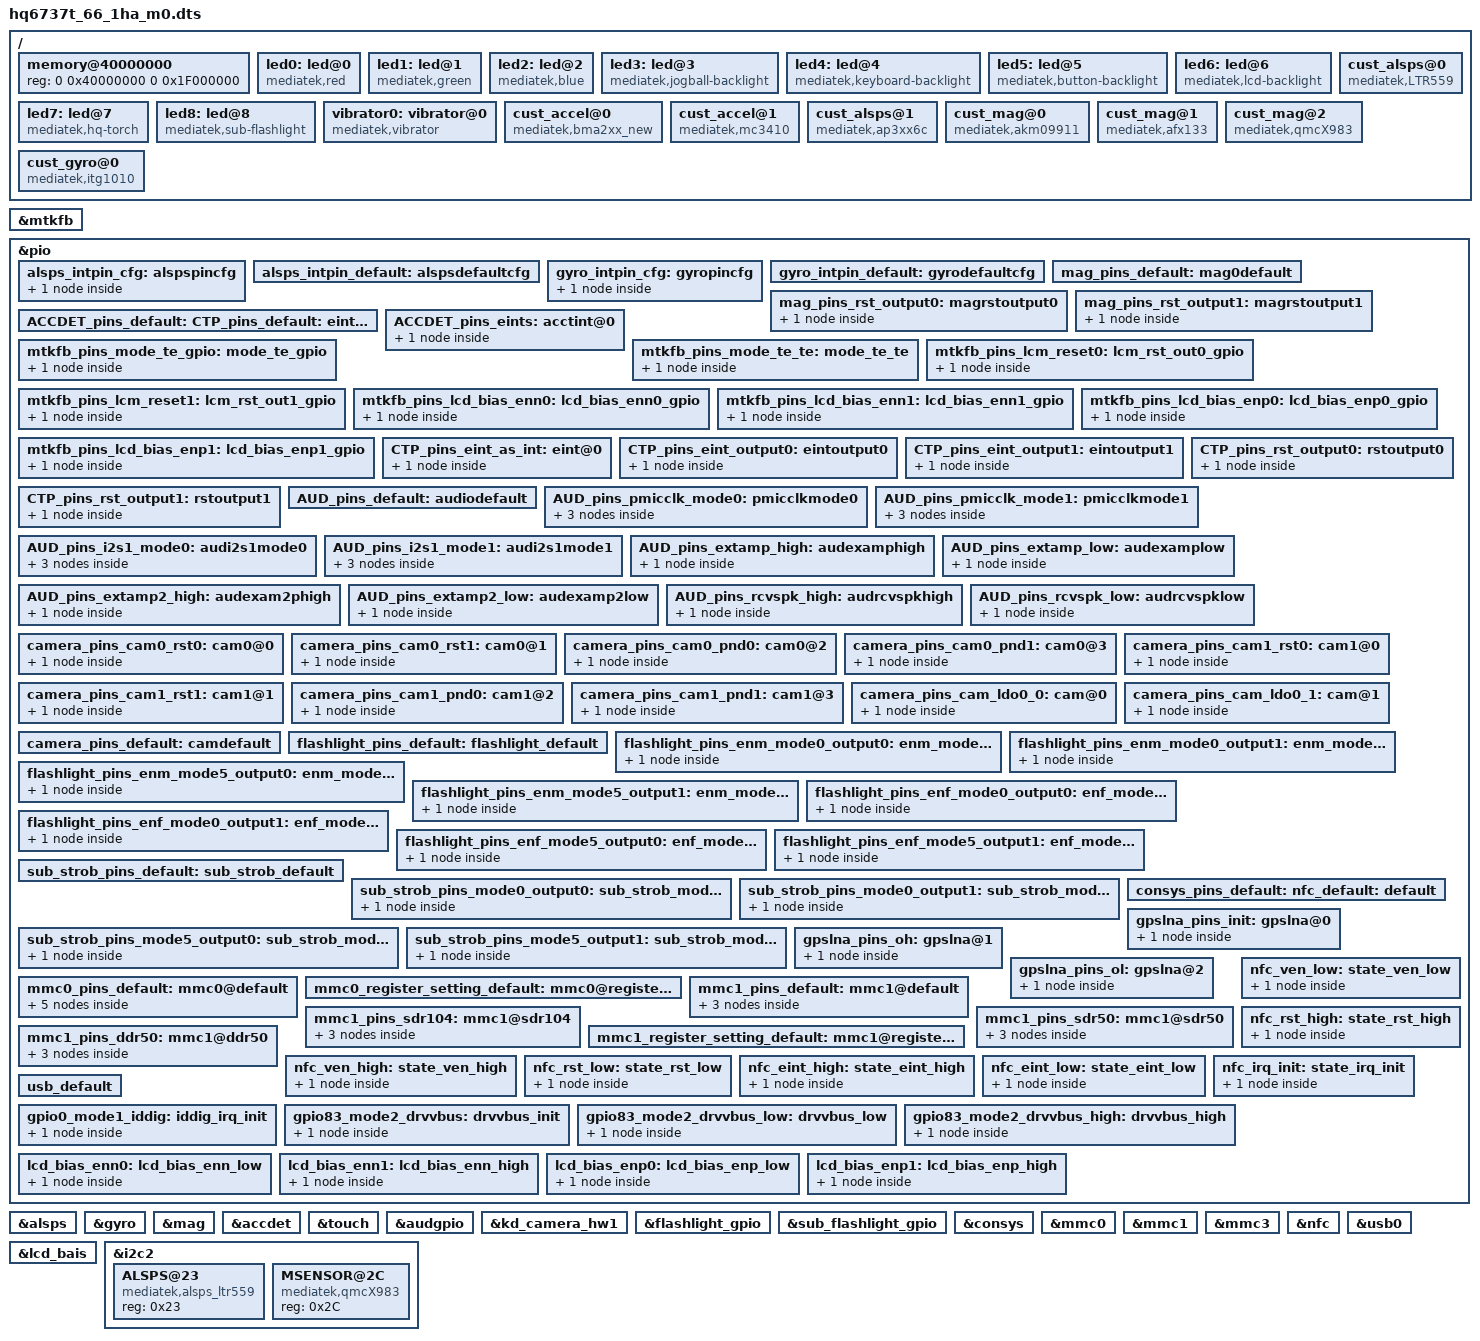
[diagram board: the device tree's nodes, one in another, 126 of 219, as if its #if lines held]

/dts-v1/;

#include "mt6735.dtsi"
#include "cust.dtsi"
#include <dt-bindings/lcm/r63417_fhd_dsi_cmd_truly_nt50358.dtsi>
#include <generated/autoconf.h>
#ifdef CONFIG_MTK_HAFG_20
#include "hq6737t_66_1ha_m0_fg20_bat_setting.dtsi"
#else
#include "hq6737t_66_1ha_m0_fg_oldgauge_bat_setting.dtsi"
#endif

/ {
	memory@40000000 {
		device_type = "memory";
		reg = <0 0x40000000 0 0x1F000000>;
	};

	led0:led@0 {
		compatible = "mediatek,red";
		led_mode = <3>;
		data = <2>;
		pwm_config = <0 0 0 0 0>;
	};
	led1:led@1 {
		compatible = "mediatek,green";
		led_mode = <3>;
		data = <1>;
		pwm_config = <0 0 0 0 0>;
	};
	led2:led@2 {
		compatible = "mediatek,blue";
		led_mode = <0>;
		data = <1>;
		pwm_config = <0 0 0 0 0>;
	};
	led3:led@3 {
		compatible = "mediatek,jogball-backlight";
		led_mode = <0>;
		data = <1>;
		pwm_config = <0 0 0 0 0>;
	};
	led4:led@4 {
		compatible = "mediatek,keyboard-backlight";
		led_mode = <0>;
		data = <1>;
		pwm_config = <0 0 0 0 0>;
	};
	led5:led@5 {
		compatible = "mediatek,button-backlight";
		led_mode = <0>;
		data = <1>;
		pwm_config = <0 0 0 0 0>;
	};
	led6:led@6 {
		compatible = "mediatek,lcd-backlight";
		led_mode = <5>;
		data = <1>;
		pwm_config = <0 0 0 0 0>;
        };
        led7:led@7 {
		compatible = "mediatek,hq-torch";
		led_mode = <1>;
		data = <1>;
		pwm_config = <0 0 0 0 0>;
	};
        led8:led@8 {
		compatible = "mediatek,sub-flashlight";
		led_mode = <1>;
		data = <1>;
		pwm_config = <0 0 0 0 0>;
	};
	vibrator0:vibrator@0 {
		compatible = "mediatek,vibrator";
		vib_timer = <25>;
		vib_limit = <9>;
		vib_vol= <6>;
	};
 /* sensor standardization */
		cust_accel@0 {
		compatible				= "mediatek,bma2xx_new";
		i2c_num				= <2>;
		i2c_addr				= <0x18 0 0 0>;
		direction				= <7>;
		power_id				= <0xffff>;
		power_vol				= <0>;
		firlen					= <0>;
		is_batch_supported			= <0>;
		};
		cust_accel@1 {
		compatible				= "mediatek,mc3410";
		i2c_num				= <2>;
		i2c_addr				= <0x4C 0 0 0>;
		direction				= <5>;
		power_id				= <0xffff>;
		power_vol				= <0>;
		firlen					= <0>;
		is_batch_supported			= <0>;
		};

		cust_alsps@0 {
		compatible				= "mediatek,LTR559";
		i2c_num				= <2>;
		i2c_addr				= <0x23 0 0 0>;
		polling_mode_ps			= <0>;
		polling_mode_als		= <1>;
		power_id				= <0xffff>;
		power_vol				= <0>;
		als_level = <0 8 15 30 70 180 300 500 800 1200 3000 5000 10000 57694 65535>;
     		als_value = <0 8 15 30 70 180 300 500 800 1200 3000 5000 10000 20000 30000 50000>;
		ps_threshold_high		=  <26>;
		ps_threshold_low		=  <21>;
		is_batch_supported_ps	= <0>;
		is_batch_supported_als	= <0>;
		};
		cust_alsps@1 {
		compatible				= "mediatek,ap3xx6c";
		i2c_num				= <2>;
		i2c_addr				= <0x1E 0 0 0>;
		polling_mode_ps			= <0>;
		polling_mode_als		= <1>;
		power_id				= <0xffff>;
		power_vol				= <0>;
		als_level = <0 328 861 1377 3125 7721 7767 12621 23062 28430 33274 47116 57694 57694 65535>;
		als_value = <0 133 304 502 1004 2005 3058 5005 8008 10010 12000 16000 20000 20000 20000 20000>;
		ps_threshold_high		=  <250>;
		ps_threshold_low		=  <65>;
		is_batch_supported_ps	= <0>;
		is_batch_supported_als	= <0>;
		};

		cust_mag@0 {
		compatible				= "mediatek,akm09911";
		i2c_num				= <2>;
		i2c_addr				= <0x0C 0 0 0>;
		direction				= <1>;
		power_id				= <0xffff>;
		power_vol				= <0>;
		is_batch_supported			= <0>;
		};
		cust_mag@1 {
		compatible				= "mediatek,afx133";
		i2c_num				= <2>;
		i2c_addr				= <0x0C 0 0 0>;
		direction				= <1>;
		power_id				= <0xffff>;
		power_vol				= <0>;
		is_batch_supported			= <0>;
		};
		cust_mag@2 {
		compatible				= "mediatek,qmcX983";
		i2c_num				= <2>;
		i2c_addr				= <0x2C 0 0 0>;
		direction				= <0>;
		power_id				= <0xffff>;
		power_vol				= <0>;
		is_batch_supported			= <0>;
		};
		cust_gyro@0 {
		compatible				= "mediatek,itg1010";
		i2c_num					= <2>;
		i2c_addr				= <0x68 0 0 0>;
		direction				= <3>;
		power_id				= <0xffff>;
		power_vol				= <0>;
		firlen					= <0>;
		is_batch_supported			= <0>;
		};
};


&mtkfb {
	reg = <0x7e000000 0x1000000>;
};

/* sensor gpio standization */
&pio {
	alsps_intpin_cfg: alspspincfg {

	    pins_cmd_dat {
			pins = <PINMUX_GPIO65__FUNC_GPIO65>;
			slew-rate = <0>;
			bias-pull-up = <00>;
		};
	};

	alsps_intpin_default: alspsdefaultcfg {

	};

	gyro_intpin_cfg: gyropincfg {

	    pins_cmd_dat {
			pins = <PINMUX_GPIO67__FUNC_GPIO67>;
			slew-rate = <0>;
			bias-pull-down = <00>;
		};
	};

	gyro_intpin_default: gyrodefaultcfg {

	};
	
	mag_pins_default: mag0default {
	};
	mag_pins_rst_output0: magrstoutput0 {
		pins_cmd_dat {
		        pins = <PINMUX_GPIO61__FUNC_GPIO61>;
			slew-rate = <1>;
			output-low;
		};
	};
	mag_pins_rst_output1: magrstoutput1 {
		pins_cmd_dat {
			pins = <PINMUX_GPIO61__FUNC_GPIO61>;
			slew-rate = <1>;
			output-high;
		};
	};
};
&alsps {
	pinctrl-names = "pin_default", "pin_cfg";
	pinctrl-0 = <&alsps_intpin_default>;
	pinctrl-1 = <&alsps_intpin_cfg>;
	status = "okay";

};

&gyro {
	pinctrl-names = "pin_default", "pin_cfg";
	pinctrl-0 = <&gyro_intpin_default>;
	pinctrl-1 = <&gyro_intpin_cfg>;
	status = "okay";

};

&mag {
	pinctrl-names = "mag_default", "mag_rst_output0", "mag_rst_output1";
	pinctrl-0 = <&mag_pins_default>;
	pinctrl-1 = <&mag_pins_rst_output0>;
	pinctrl-2 = <&mag_pins_rst_output1>;
	status = "okay";
};
/* sensor end */
&accdet {
		accdet-mic-vol = <7>;
		headset-mode-setting = <0x500 0x600 1 0x1F0 0x700 0x800 0x20>;
		accdet-plugout-debounce = <20>;
		/*1:ACC mode, 2:low cost without in bias, 6:low cost with in bias*/
		accdet-mic-mode = <1>;
		/*0--MD_MAX--UP_MAX--DW_MAX*/
		headset-three-key-threshold = <0 80 220 500>;
		/*0--MD_MAX--VOICE_MAX--UP_MAX--DW_MAX*/
		headset-four-key-threshold = <0 58 121 192 450>;
		debounce = <0x6 0x3E800>;
		pinctrl-names = "default", "state_eint_as_int";
		pinctrl-0 = <&ACCDET_pins_default>;
		pinctrl-1 = <&ACCDET_pins_eints>;
		status = "okay";
};
		

&pio {
    ACCDET_pins_default: eint0default {
                
    };
    ACCDET_pins_eints: acctint@0{
        pins_cmd_dat {
                        pins = <PINMUX_GPIO6__FUNC_GPIO6>;
                        slew-rate = <0>;
                        bias-disable;
                    
      		  };    
    };
};
&touch {
	tpd-resolution = <1080 1920>;
	use-tpd-button = <0>;
	tpd-key-num = <3>;
	tpd-key-local= <139 172 158 0>;
	tpd-key-dim-local = <90 883 100 40 230 883 100 40 370 883 100 40 0 0 0 0>;
	tpd-max-touch-num = <5>;
	tpd-filter-enable = <1>;
	tpd-filter-pixel-density = <186>;
	tpd-filter-custom-prameters = <0 0 0 0 0 0 0 0 0 0 0 0>;
	tpd-filter-custom-speed = <0 0 0>;
	pinctrl-names = "default", "state_eint_as_int", "state_eint_output0", "state_eint_output1",
		"state_rst_output0", "state_rst_output1";
	pinctrl-0 = <&CTP_pins_default>;
	pinctrl-1 = <&CTP_pins_eint_as_int>;
	pinctrl-2 = <&CTP_pins_eint_output0>;
	pinctrl-3 = <&CTP_pins_eint_output1>;
	pinctrl-4 = <&CTP_pins_rst_output0>;
	pinctrl-5 = <&CTP_pins_rst_output1>;
	status = "okay";
};
/*
&mtkfb {
	reg = <0x7f000000 0x1000000>;
};
*/
/* DISPSYS GPIO start */
&mtkfb {
	pinctrl-names = "mode_te_gpio", "mode_te_te", "lcm_rst_out0_gpio",
			"lcm_rst_out1_gpio", "lcd_bias_enn0_gpio", "lcd_bias_enn1_gpio",
			"lcd_bias_enp0_gpio", "lcd_bias_enp1_gpio", "lcd_power_enable0_gpio", "lcd_power_enable1_gpio";
	pinctrl-0 = <&mtkfb_pins_mode_te_gpio>;
	pinctrl-1 = <&mtkfb_pins_mode_te_te>;
	pinctrl-2 = <&mtkfb_pins_lcm_reset0>;
	pinctrl-3 = <&mtkfb_pins_lcm_reset1>;
	pinctrl-4 = <&mtkfb_pins_lcd_bias_enn0>;
	pinctrl-5 = <&mtkfb_pins_lcd_bias_enn1>;
	pinctrl-6 = <&mtkfb_pins_lcd_bias_enp0>;
	pinctrl-7 = <&mtkfb_pins_lcd_bias_enp1>;
	status = "okay";
};
&pio {
	mtkfb_pins_mode_te_gpio: mode_te_gpio {
		pins_cmd_dat {
			pins = <PINMUX_GPIO147__FUNC_DSI_TE>;
		};
	};
	mtkfb_pins_mode_te_te: mode_te_te {
		pins_cmd_dat {
			pins = <PINMUX_GPIO147__FUNC_DSI_TE>;
		};
	};
	mtkfb_pins_lcm_reset0: lcm_rst_out0_gpio {
		pins_cmd_dat {
			pins = <PINMUX_GPIO146__FUNC_GPIO146>;
			slew-rate = <1>;
			output-low;
		};
	};
	mtkfb_pins_lcm_reset1: lcm_rst_out1_gpio {
		pins_cmd_dat {
			pins = <PINMUX_GPIO146__FUNC_GPIO146>;
			slew-rate = <1>;
			output-high;
		};
	};
	mtkfb_pins_lcd_bias_enn0: lcd_bias_enn0_gpio {
		pins_cmd_dat {
			pins = <PINMUX_GPIO63__FUNC_GPIO63>;
			slew-rate = <1>;
			output-low;
		};
	};
	mtkfb_pins_lcd_bias_enn1: lcd_bias_enn1_gpio {
		pins_cmd_dat {
			pins = <PINMUX_GPIO63__FUNC_GPIO63>;
			slew-rate = <1>;
			output-high;
		};
	};
	mtkfb_pins_lcd_bias_enp0: lcd_bias_enp0_gpio {
		pins_cmd_dat {
			pins = <PINMUX_GPIO64__FUNC_GPIO64>;
			slew-rate = <1>;
			output-low;
		};
	};
	mtkfb_pins_lcd_bias_enp1: lcd_bias_enp1_gpio {
		pins_cmd_dat {
			pins = <PINMUX_GPIO64__FUNC_GPIO64>;
			slew-rate = <1>;
			output-high;
		};
	};

};
/* DISPSYS GPIO end */


&pio {
	CTP_pins_default: eint0default {
	};
	CTP_pins_eint_as_int: eint@0 {
		pins_cmd_dat {
			pins = <PINMUX_GPIO10__FUNC_GPIO10>;
			slew-rate = <0>;
			bias-disable;
		};
	};
	CTP_pins_eint_output0: eintoutput0 {
		pins_cmd_dat {
			pins = <PINMUX_GPIO10__FUNC_GPIO10>;
			slew-rate = <1>;
			output-low;
		};
	};
	CTP_pins_eint_output1: eintoutput1 {
		pins_cmd_dat {
			pins = <PINMUX_GPIO10__FUNC_GPIO10>;
			slew-rate = <1>;
			output-high;
		};
	};
	CTP_pins_rst_output0: rstoutput0 {
		pins_cmd_dat {
			pins = <PINMUX_GPIO62__FUNC_GPIO62>;
			slew-rate = <1>;
			output-low;
		};
	};
	CTP_pins_rst_output1: rstoutput1 {
		pins_cmd_dat {
			pins = <PINMUX_GPIO62__FUNC_GPIO62>;
			slew-rate = <1>;
			output-high;
		};
	};
};
/* TOUCH end */
/* AUDIO GPIO standardization */
&audgpio {
	pinctrl-names = "default", "audpmicclk-mode0", "audpmicclk-mode1", "audi2s1-mode0", "audi2s1-mode1", "extamp-pullhigh", "extamp-pulllow", "extamp2-pullhigh", "extamp2-pulllow", "rcvspk-pullhigh", "rcvspk-pulllow";
	pinctrl-0 = <&AUD_pins_default>;
	pinctrl-1 = <&AUD_pins_pmicclk_mode0>;
	pinctrl-2 = <&AUD_pins_pmicclk_mode1>;
	pinctrl-3 = <&AUD_pins_i2s1_mode0>;
	pinctrl-4 = <&AUD_pins_i2s1_mode1>;
	pinctrl-5 = <&AUD_pins_extamp_high>;
	pinctrl-6 = <&AUD_pins_extamp_low>;
	pinctrl-7 = <&AUD_pins_extamp2_high>;
	pinctrl-8 = <&AUD_pins_extamp2_low>;
	pinctrl-9 = <&AUD_pins_rcvspk_high>;
	pinctrl-10 = <&AUD_pins_rcvspk_low>;
	status = "okay";
};
&pio {
	AUD_pins_default: audiodefault {
	};
	AUD_pins_pmicclk_mode0: pmicclkmode0 {
		pins_cmd0_dat {
			pins = <PINMUX_GPIO143__FUNC_GPIO143>;
		};
		pins_cmd1_dat {
			pins = <PINMUX_GPIO144__FUNC_GPIO144>;
		};
		pins_cmd2_dat {
			pins = <PINMUX_GPIO145__FUNC_GPIO145>;
		};
	};
	AUD_pins_pmicclk_mode1: pmicclkmode1 {
		pins_cmd0_dat {
			pins = <PINMUX_GPIO143__FUNC_AUD_CLK_MOSI>;
		};
		pins_cmd1_dat {
			pins = <PINMUX_GPIO144__FUNC_AUD_DAT_MISO>;
		};
		pins_cmd2_dat {
			pins = <PINMUX_GPIO145__FUNC_AUD_DAT_MOSI>;
		};
	};
	AUD_pins_i2s1_mode0: audi2s1mode0 {
		pins_cmd0_dat {
			pins = <PINMUX_GPIO78__FUNC_GPIO78>;
		};
		pins_cmd1_dat {
			pins = <PINMUX_GPIO79__FUNC_GPIO79>;
		};
		pins_cmd2_dat {
			pins = <PINMUX_GPIO80__FUNC_GPIO80>;
		};
	};
	AUD_pins_i2s1_mode1: audi2s1mode1 {
		pins_cmd0_dat {
			pins = <PINMUX_GPIO78__FUNC_I2S0_DI>;
		};
		pins_cmd1_dat {
			pins = <PINMUX_GPIO79__FUNC_I2S0_LRCK>;
		};
		pins_cmd2_dat {
			pins = <PINMUX_GPIO80__FUNC_I2S0_BCK>;
		};
	};
	AUD_pins_extamp_high: audexamphigh {
		pins_cmd_dat {
			pins = <PINMUX_GPIO68__FUNC_GPIO68>;
				slew-rate = <1>;
				output-high;
		};
	};
	AUD_pins_extamp_low: audexamplow {
		pins_cmd_dat {
			pins = <PINMUX_GPIO68__FUNC_GPIO68>;
				slew-rate = <1>;
				output-low;
		};
	};
	AUD_pins_extamp2_high: audexam2phigh {
		pins_cmd_dat {
			pins = <PINMUX_GPIO128__FUNC_GPIO128>;
				slew-rate = <1>;
				output-high;
		};
	};
	AUD_pins_extamp2_low: audexamp2low {
		pins_cmd_dat {
			pins = <PINMUX_GPIO128__FUNC_GPIO128>;
				slew-rate = <1>;
				output-low;
		};
	};
	AUD_pins_rcvspk_high: audrcvspkhigh {
		pins_cmd_dat {
			pins = <PINMUX_GPIO120__FUNC_GPIO120>;
				slew-rate = <1>;
				output-high;
		};
	};
	AUD_pins_rcvspk_low: audrcvspklow {
		pins_cmd_dat {
			pins = <PINMUX_GPIO120__FUNC_GPIO120>;
				slew-rate = <1>;
				output-low;
		};
	};
};
/* AUDIO end */
/* CAMERA GPIO standardization */
&pio {
	camera_pins_cam0_rst0: cam0@0 {
		pins_cmd_dat {
			pins = <PINMUX_GPIO44__FUNC_GPIO44>;/*GPIO_CAMERA_CMRST_PIN*/
			slew-rate = <1>; /*direction 0:in, 1:out*/
			output-low;/*direction out used only. output_low or high*/
		};
	};
	camera_pins_cam0_rst1: cam0@1 {
		pins_cmd_dat {
			pins = <PINMUX_GPIO44__FUNC_GPIO44>;/*GPIO_CAMERA_CMRST_PIN*/
			slew-rate = <1>;
			output-high;
		};
	};
	camera_pins_cam0_pnd0: cam0@2 {
		pins_cmd_dat {
			pins = <PINMUX_GPIO59__FUNC_GPIO59>;/*GPIO_CAMERA_CMPDN_PIN*/
			slew-rate = <1>;
			output-low;
		};
	};
	camera_pins_cam0_pnd1: cam0@3 {
		pins_cmd_dat {
			pins = <PINMUX_GPIO59__FUNC_GPIO59>;/*GPIO_CAMERA_CMPDN_PIN*/
			slew-rate = <1>;
			output-high;
		};
	};
	camera_pins_cam1_rst0: cam1@0 {
		pins_cmd_dat {
			pins = <PINMUX_GPIO11__FUNC_GPIO11>;/*GPIO_CAMERA_CMRST1_PIN*/
			slew-rate = <1>; /*direction 0:in, 1:out*/
			output-low;/*direction out used only. output_low or high*/
		};
	};
	camera_pins_cam1_rst1: cam1@1 {
		pins_cmd_dat {
			pins = <PINMUX_GPIO11__FUNC_GPIO11>;/*GPIO_CAMERA_CMRST1_PIN*/
			slew-rate = <1>;
			output-high;
		};
	};
	camera_pins_cam1_pnd0: cam1@2 {
		pins_cmd_dat {
			pins = <PINMUX_GPIO12__FUNC_GPIO12>;/*GPIO_CAMERA_CMPDN1_PIN*/
			slew-rate = <1>;
			output-low;
		};
	};
	camera_pins_cam1_pnd1: cam1@3 {
		pins_cmd_dat {
			pins = <PINMUX_GPIO12__FUNC_GPIO12>;/*GPIO_CAMERA_CMPDN1_PIN*/
			slew-rate = <1>;
			output-high;
		};
	};
	camera_pins_cam_ldo0_0: cam@0 {
		pins_cmd_dat {
			pins = <PINMUX_GPIO68__FUNC_GPIO68>;
			slew-rate = <1>;
			output-low;
		};
	};
	camera_pins_cam_ldo0_1: cam@1 {
		pins_cmd_dat {
			pins = <PINMUX_GPIO68__FUNC_GPIO68>;
			slew-rate = <1>;
			output-high;
		};
	};
	camera_pins_default: camdefault {

	};
};

&kd_camera_hw1 {
	pinctrl-names = "default", "cam0_rst0", "cam0_rst1", "cam0_pnd0", "cam0_pnd1",
	"cam1_rst0", "cam1_rst1", "cam1_pnd0", "cam1_pnd1",
	"cam_ldo0_0", "cam_ldo0_1";
	pinctrl-0 = <&camera_pins_default>;
	pinctrl-1 = <&camera_pins_cam0_rst0>;
	pinctrl-2 = <&camera_pins_cam0_rst1>;
	pinctrl-3 = <&camera_pins_cam0_pnd0>;
	pinctrl-4 = <&camera_pins_cam0_pnd1>;
	pinctrl-5 = <&camera_pins_cam1_rst0>;
	pinctrl-6 = <&camera_pins_cam1_rst1>;
	pinctrl-7 = <&camera_pins_cam1_pnd0>;
	pinctrl-8 = <&camera_pins_cam1_pnd1>;
	pinctrl-9 = <&camera_pins_cam_ldo0_0>;
	pinctrl-10 = <&camera_pins_cam_ldo0_1>;
	status = "okay";

};
/* CAMERA GPIO end */
/********flashlight gpio start************/

&pio {
	flashlight_pins_default: flashlight_default {
	};
	/*torch_en*/
	flashlight_pins_enm_mode0_output0: enm_mode0@0 {
	    pins_cmd_dat {
			pins = <PINMUX_GPIO78__FUNC_GPIO78>;/*GPIO_FL_ENM_PIN*/
			slew-rate = <1>; /*direction 0:in, 1:out*/
			output-low;/*direction out used only. output_low or high*/
		};
	};
	
	flashlight_pins_enm_mode0_output1: enm_mode0@1 {
	    pins_cmd_dat {
			pins = <PINMUX_GPIO78__FUNC_GPIO78>;/*GPIO_DISP_ENN_PIN*/
			slew-rate = <1>; /*direction 0:in, 1:out*/
			output-high;/*direction out used only. output_low or high*/
		};
	};
	flashlight_pins_enm_mode5_output0: enm_mode5@0 {
	    pins_cmd_dat {
			pins = <PINMUX_GPIO78__FUNC_PWM0>;/*GPIO_DISP_ENP_PIN*/
			slew-rate = <1>;
			bias-disable;
		};
	};
	flashlight_pins_enm_mode5_output1: enm_mode5@1 {
	    pins_cmd_dat {
			pins = <PINMUX_GPIO78__FUNC_PWM0>;/*GPIO_DISP_ENP_PIN*/
			slew-rate = <1>;
			bias-disable;
		};
	};
	
	/*flash*/
	flashlight_pins_enf_mode0_output0: enf_mode0@0 {
	    pins_cmd_dat {
			pins = <PINMUX_GPIO80__FUNC_GPIO80>;/*GPIO_DISP_ENP_PIN*/
			slew-rate = <1>;
			output-low;
		};
	};
	flashlight_pins_enf_mode0_output1: enf_mode0@1 {
	    pins_cmd_dat {
			pins = <PINMUX_GPIO80__FUNC_GPIO80>;/*GPIO_DISP_ENP_PIN*/
			slew-rate = <1>;
			output-high;
		};
	};
	flashlight_pins_enf_mode5_output0: enf_mode5@0 {
	    pins_cmd_dat {
			pins = <PINMUX_GPIO80__FUNC_PWM4>;/*GPIO_DISP_ENP_PIN*/
			slew-rate = <1>;
			output-high;
		};
	};
	flashlight_pins_enf_mode5_output1: enf_mode5@1 {
	    pins_cmd_dat {
			pins = <PINMUX_GPIO80__FUNC_PWM4>;/*GPIO_DISP_ENP_PIN*/
			slew-rate = <1>;
			output-high;
		};
	};
	
	

	
};

&flashlight_gpio {
	pinctrl-names = "flashlight_default", "flashlight_enm_mode0_l", "flashlight_enm_mode0_h", "flashlight_enm_mode5_l", "flashlight_enm_mode5_h",
	"flashlight_enf_mode0_l","flashlight_enf_mode0_h","flashlight_enf_mode5_l","flashlight_enf_mode5_h";
	pinctrl-0 = <&flashlight_pins_default>;	
	pinctrl-1 = <&flashlight_pins_enm_mode0_output0>;
	pinctrl-2 = <&flashlight_pins_enm_mode0_output1>;
	pinctrl-3 = <&flashlight_pins_enm_mode5_output0>;
	pinctrl-4 = <&flashlight_pins_enm_mode5_output1>;
	
	pinctrl-5 = <&flashlight_pins_enf_mode0_output0>;
	pinctrl-6 = <&flashlight_pins_enf_mode0_output1>;
	pinctrl-7 = <&flashlight_pins_enf_mode5_output0>;
	pinctrl-8 = <&flashlight_pins_enf_mode5_output1>;
	
	
	
	status = "okay";

};
&pio {
	sub_strob_pins_default: sub_strob_default {
	};
	/*sub_strob_en*/
	sub_strob_pins_mode0_output0: sub_strob_mode0@0 {
	    pins_cmd_dat {
			pins = <PINMUX_GPIO0__FUNC_GPIO0>;/*GPIO_FL_ENM_PIN*/
			slew-rate = <1>; /*direction 0:in, 1:out*/
			output-low;/*direction out used only. output_low or high*/
		};
	};
	
	sub_strob_pins_mode0_output1: sub_strob_mode0@1 {
	    pins_cmd_dat {
			pins = <PINMUX_GPIO0__FUNC_GPIO0>;/*GPIO_DISP_ENN_PIN*/
			slew-rate = <1>; /*direction 0:in, 1:out*/
			output-high;/*direction out used only. output_low or high*/
		};
	};
	sub_strob_pins_mode5_output0: sub_strob_mode5@0 {
	    pins_cmd_dat {
			pins = <PINMUX_GPIO0__FUNC_PWM3>;/*GPIO_DISP_ENP_PIN*/
			slew-rate = <1>;
			output-high;
		};
	};
	sub_strob_pins_mode5_output1: sub_strob_mode5@1 {
	    pins_cmd_dat {
			pins = <PINMUX_GPIO0__FUNC_PWM3>;/*GPIO_DISP_ENP_PIN*/
			slew-rate = <1>;
			output-high;
		};
	};	
};
&sub_flashlight_gpio
{
	pinctrl-names = "sub_strob_default", "sub_strob_gpio_out_l", "sub_strob_gpio_out_h", "sub_strob_pwm_out_l" ,"sub_strob_pwm_out_h";
	pinctrl-0 = <&sub_strob_pins_default>;	
	pinctrl-1 = <&sub_strob_pins_mode0_output0>;
	pinctrl-2 = <&sub_strob_pins_mode0_output1>;
	pinctrl-3 = <&sub_strob_pins_mode5_output0>;
	pinctrl-4 = <&sub_strob_pins_mode5_output1>;
	
	status = "okay";

};
/*****flashlight gpio end********/
/* CONSYS GPIO standardization */
&pio {
	consys_pins_default: default {

	};

	gpslna_pins_init: gpslna@0 {

	    pins_cmd_dat {
			pins = <PINMUX_GPIO79__FUNC_GPIO79>;
			slew-rate = <0>;
			bias-disable;
			output-low;
		};
	};

	gpslna_pins_oh: gpslna@1 {

	    pins_cmd_dat {
			pins = <PINMUX_GPIO79__FUNC_GPIO79>;
			slew-rate = <1>;
			output-high;
		};
	};

	gpslna_pins_ol: gpslna@2 {

	    pins_cmd_dat {
			pins = <PINMUX_GPIO79__FUNC_GPIO79>;
			slew-rate = <1>;
			output-low;
		};
	};

};

&consys {
	pinctrl-names = "default", "gps_lna_state_init", "gps_lna_state_oh", "gps_lna_state_ol";
	pinctrl-0 = <&consys_pins_default>;
	pinctrl-1 = <&gpslna_pins_init>;
	pinctrl-2 = <&gpslna_pins_oh>;
	pinctrl-3 = <&gpslna_pins_ol>;
	status = "okay";

};
/* CONSYS end */

/* mmc start */
&mmc0 {
		clk_src = /bits/ 8 <MSDC50_CLKSRC_400MHZ>;
		bus-width = <8>;
		max-frequency = <200000000>;
		cap-mmc-highspeed;
		msdc-sys-suspend;
		mmc-ddr-1_8v;
		mmc-hs200-1_8v;
		mmc-hs400-1_8v;
		non-removable;
		pinctl = <&mmc0_pins_default>;
		register_setting = <&mmc0_register_setting_default>;
		host_function = /bits/ 8 <MSDC_EMMC>;
		bootable;
		status = "okay";
};

&mmc1 {
		clk_src = /bits/ 8 <MSDC30_CLKSRC_200MHZ>;
		bus-width = <4>;
		max-frequency = <200000000>;
		msdc-sys-suspend;
		cap-sd-highspeed;
		sd-uhs-sdr12;
		sd-uhs-sdr25;
		sd-uhs-sdr50;
		sd-uhs-sdr104;
		sd-uhs-ddr50;
		pinctl = <&mmc1_pins_default>;
		pinctl_sdr104 = <&mmc1_pins_sdr104>;
		pinctl_sdr50 = <&mmc1_pins_sdr50>;
		pinctl_ddr50 = <&mmc1_pins_ddr50>;
		register_setting = <&mmc1_register_setting_default>;
		host_function = /bits/ 8 <MSDC_SD>;
		cd_level = /bits/ 8 <MSDC_CD_LOW>;
		cd-gpios = <&pio 5 0>;
		status = "okay";
};

&mmc3 {
		clk_src = /bits/ 8 <MSDC30_CLKSRC_200MHZ>;
		bus-width = <4>;
		max-frequency = <50000000>;
		cap-sd-highspeed;
		sd-uhs-sdr12;
		sd-uhs-sdr25;
		sd-uhs-sdr50;
		host_function = /bits/ 8 <MSDC_SDIO>;
		non-removable;
		status = "okay";
};

&pio {
	mmc0_pins_default: mmc0@default {
			pins_cmd {
				drive-strength = /bits/ 8 <2>;
			};
			pins_dat {
				drive-strength = /bits/ 8 <2>;
			};
			pins_clk {
				drive-strength = /bits/ 8 <2>;
			};
			pins_rst {
				drive-strength = /bits/ 8 <2>;
			};
			pins_ds {
				drive-strength = /bits/ 8 <2>;
			};
	};

	mmc0_register_setting_default: mmc0@register_default {
		dat0rddly      = /bits/ 8 <0>;
		dat1rddly      = /bits/ 8 <0>;
		dat2rddly      = /bits/ 8 <0>;
		dat3rddly      = /bits/ 8 <0>;
		dat4rddly      = /bits/ 8 <0>;
		dat5rddly      = /bits/ 8 <0>;
		dat6rddly      = /bits/ 8 <0>;
		dat7rddly      = /bits/ 8 <0>;
		datwrddly      = /bits/ 8 <0>;
		cmdrrddly      = /bits/ 8 <0>;
		cmdrddly       = /bits/ 8 <0>;
		cmd_edge = /bits/ 8 <MSDC_SMPL_FALLING>;
		rdata_edge = /bits/ 8 <MSDC_SMPL_FALLING>;
		wdata_edge = /bits/ 8 <MSDC_SMPL_FALLING>;

		ett-hs200-cells = <12>;
		ett-hs200-default = <OFFSET_MSDC_PATCH_BIT0	MSDC_PB0_INT_DAT_LATCH_CK_SEL 0x0
			OFFSET_MSDC_PATCH_BIT0	MSDC_PB0_CKGEN_MSDC_DLY_SEL   0x0
			OFFSET_MSDC_PATCH_BIT1	MSDC_PB1_CMD_RSP_TA_CNTR      0x1
			OFFSET_MSDC_IOCON		MSDC_IOCON_RSPL               0x0
			OFFSET_MSDC_PAD_TUNE0	MSDC_PAD_TUNE0_CMDRDLY        0x7
			OFFSET_MSDC_PAD_TUNE0	MSDC_PAD_TUNE0_CMDRRDLY       0xb
			OFFSET_MSDC_PATCH_BIT1		MSDC_PB1_WRDAT_CRCS_TA_CNTR   0x1
			OFFSET_MSDC_PAD_TUNE0	MSDC_PAD_TUNE0_DATWRDLY       0xb
			OFFSET_MSDC_IOCON			MSDC_IOCON_W_D0SPL            0x0
			OFFSET_MSDC_DAT_RDDLY0		MSDC_DAT_RDDLY0_D0            0x7
			OFFSET_MSDC_PAD_TUNE0	MSDC_PAD_TUNE0_DATRRDLY       0x9
			OFFSET_MSDC_IOCON		MSDC_IOCON_R_D_SMPL           0x0>;

		ett-hs400-cells = <8>;
		ett-hs400-default = <OFFSET_MSDC_PATCH_BIT0	MSDC_PB0_INT_DAT_LATCH_CK_SEL	0x0
			OFFSET_MSDC_PATCH_BIT0		MSDC_PB0_CKGEN_MSDC_DLY_SEL		0x0
			OFFSET_EMMC50_PAD_DS_TUNE	MSDC_EMMC50_PAD_DS_TUNE_DLY1	0x2
			OFFSET_EMMC50_PAD_DS_TUNE	MSDC_EMMC50_PAD_DS_TUNE_DLY3	0x10
			OFFSET_MSDC_PATCH_BIT1			MSDC_PB1_CMD_RSP_TA_CNTR	0x1
			OFFSET_MSDC_IOCON		MSDC_IOCON_RSPL				0x0
			OFFSET_MSDC_PAD_TUNE0			MSDC_PAD_TUNE0_CMDRDLY		0x6
			OFFSET_MSDC_PAD_TUNE0		MSDC_PAD_TUNE0_CMDRRDLY		0x6>;
	};

	mmc1_pins_default: mmc1@default {
			pins_cmd {
				drive-strength = /bits/ 8 <3>;
			};
			pins_dat {
				drive-strength = /bits/ 8 <3>;
			};
			pins_clk {
				drive-strength = /bits/ 8 <3>;
			};
	};

	mmc1_pins_sdr104: mmc1@sdr104 {
			pins_cmd {
				drive-strength = /bits/ 8 <2>;
			};
			pins_dat {
				drive-strength = /bits/ 8 <2>;
			};
			pins_clk {
				drive-strength = /bits/ 8 <3>;
			};
	};

	mmc1_pins_sdr50: mmc1@sdr50 {
			pins_cmd {
				drive-strength = /bits/ 8 <2>;
			};
			pins_dat {
				drive-strength = /bits/ 8 <2>;
			};
			pins_clk {
				drive-strength = /bits/ 8 <3>;
			};
	};

	mmc1_pins_ddr50: mmc1@ddr50 {
			pins_cmd {
				drive-strength = /bits/ 8 <2>;
			};
			pins_dat {
				drive-strength = /bits/ 8 <2>;
			};
			pins_clk {
				drive-strength = /bits/ 8 <3>;
			};
	};

	mmc1_register_setting_default: mmc1@register_default {
				dat0rddly      = /bits/ 8 <0>;
				dat1rddly      = /bits/ 8 <0>;
				dat2rddly      = /bits/ 8 <0>;
				dat3rddly      = /bits/ 8 <0>;
				datwrddly      = /bits/ 8 <0>;
				cmdrrddly      = /bits/ 8 <0>;
				cmdrddly       = /bits/ 8 <0>;
				cmd_edge = /bits/ 8 <MSDC_SMPL_FALLING>;
				rdata_edge = /bits/ 8 <MSDC_SMPL_FALLING>;
				wdata_edge = /bits/ 8 <MSDC_SMPL_FALLING>;
	};
};
/* mmc end */

/* NFC GPIO standardization */
&pio {
	nfc_default: default {

	};

	nfc_ven_high: state_ven_high {
	    pins_cmd_dat {
		pins = <PINMUX_GPIO4__FUNC_GPIO4>;
		slew-rate = <1>;
		output-high;
	    };
	};

	nfc_ven_low: state_ven_low {
	    pins_cmd_dat {
		pins = <PINMUX_GPIO4__FUNC_GPIO4>;
		slew-rate = <1>;
		output-low;
	    };
	};

	nfc_rst_high: state_rst_high {
	    pins_cmd_dat {
		pins = <PINMUX_GPIO3__FUNC_GPIO3>;
		slew-rate = <1>;
		output-high;
	    };
	};

	nfc_rst_low: state_rst_low {
	    pins_cmd_dat {
		pins = <PINMUX_GPIO3__FUNC_GPIO3>;
		slew-rate = <1>;
		output-low;
	    };
	};

	nfc_eint_high: state_eint_high {
	    pins_cmd_dat {
		pins = <PINMUX_GPIO1__FUNC_GPIO1>;
		slew-rate = <1>;
		output-high;
	    };
	};

	nfc_eint_low: state_eint_low {
	    pins_cmd_dat {
		pins = <PINMUX_GPIO1__FUNC_GPIO1>;
		slew-rate = <1>;
		output-low;
	    };
	};

	nfc_irq_init: state_irq_init {
	    pins_cmd_dat {
		pins = <PINMUX_GPIO2__FUNC_GPIO2>;
		slew-rate = <0>;
		bias-pull-down = <00>;
	    };
	};
};

&nfc {
	pinctrl-names = "default", "ven_high", "ven_low", "rst_high", "rst_low", "eint_high", "eint_low", "irq_init";
	pinctrl-0 = <&nfc_default>;
	pinctrl-1 = <&nfc_ven_high>;
	pinctrl-2 = <&nfc_ven_low>;
	pinctrl-3 = <&nfc_rst_high>;
	pinctrl-4 = <&nfc_rst_low>;
	pinctrl-5 = <&nfc_eint_high>;
	pinctrl-6 = <&nfc_eint_low>;
	pinctrl-7 = <&nfc_irq_init>;
	status = "okay";
};
/* NFC end */

/* USB GPIO Kernal Standardization start */
&pio {
	usb_default: usb_default {
	};

	gpio0_mode1_iddig: iddig_irq_init {
		pins_cmd_dat {
			pins = <PINMUX_GPIO0__FUNC_IDDIG>;
			slew-rate = <0>;
			bias-pull-up = <00>;
		};
	};

	gpio83_mode2_drvvbus: drvvbus_init {
		pins_cmd_dat {
			pins = <PINMUX_GPIO83__FUNC_GPIO83>;
			slew-rate = <1>;
			bias-pull-down = <00>;
		};
	};

	gpio83_mode2_drvvbus_low: drvvbus_low {
		pins_cmd_dat {
			pins = <PINMUX_GPIO83__FUNC_GPIO83>;
			slew-rate = <1>;
			output-low;
			bias-pull-down = <00>;
		};
	};

	gpio83_mode2_drvvbus_high: drvvbus_high {
		pins_cmd_dat {
			pins = <PINMUX_GPIO83__FUNC_GPIO83>;
			slew-rate = <1>;
			output-high;
			bias-pull-down = <00>;
		};
	};
};

&usb0 {
	iddig_gpio = <0 1>;
	pinctrl-names = "usb_default", "iddig_irq_init", "drvvbus_init", "drvvbus_low", "drvvbus_high";
	pinctrl-0 = <&usb_default>;
	pinctrl-1 = <&gpio0_mode1_iddig>;
	pinctrl-2 = <&gpio83_mode2_drvvbus>;
	pinctrl-3 = <&gpio83_mode2_drvvbus_low>;
	pinctrl-4 = <&gpio83_mode2_drvvbus_high>;
	status = "okay";
};
/* USB GPIO Kernal Standardization end */
/*lcd_bais pinctrl end*/
&pio {
	lcd_bias_enn0: lcd_bias_enn_low {
		pins_cmd_dat {
			pins = <PINMUX_GPIO63__FUNC_GPIO63>;
			slew-rate = <1>;
			output-low;
		};
	};
	lcd_bias_enn1: lcd_bias_enn_high {
		pins_cmd_dat {
			pins = <PINMUX_GPIO63__FUNC_GPIO63>;
			slew-rate = <1>;
			output-high;
		};
	};
	lcd_bias_enp0: lcd_bias_enp_low {
		pins_cmd_dat {
			pins = <PINMUX_GPIO64__FUNC_GPIO64>;
			slew-rate = <1>;
			output-low;
		};
	};
	lcd_bias_enp1: lcd_bias_enp_high {
		pins_cmd_dat {
			pins = <PINMUX_GPIO64__FUNC_GPIO64>;
			slew-rate = <1>;
			output-high;
		};
	};
};
&lcd_bais {
	pinctrl-names = "lcd_bias_enn_low", "lcd_bias_enn_high",
									"lcd_bias_enp_low", "lcd_bias_enp_high";
	pinctrl-0 = <&lcd_bias_enn0>;
	pinctrl-1 = <&lcd_bias_enn1>;
	pinctrl-2 = <&lcd_bias_enp0>;
	pinctrl-3 = <&lcd_bias_enp1>;
	status = "okay";
};
/*lcd_bais pinctrl end*/

&i2c2{
	ALSPS@23{
	compatible = "mediatek,alsps_ltr559"; 
	reg = <0x23>;
	};
	MSENSOR@2C{
	compatible = "mediatek,qmcX983"; 
	reg = <0x2C>;
	};
};

